# PIC32MM0064GPL036 register map
Vendor: Microchip
Registers are 32-bit, read-write, reset 0x0 unless marked. A register's access mark holds for its fields unless they carry their own. Addresses are absolute, and some are shared; only a register's first bit layout is shown; [hi:lo] are bit positions; {n}, {i} and the like mark numbered series.

## HLVD
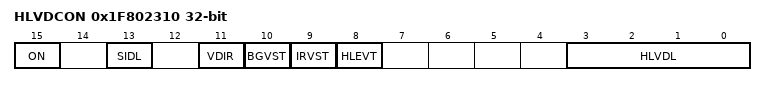
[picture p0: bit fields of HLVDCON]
0x1F802310 HLVDCON
  [15] ON, [13] SIDL, [11] VDIR, [10] BGVST, [9] IRVST, [8] HLEVT, [3:0] HLVDL

## NVM
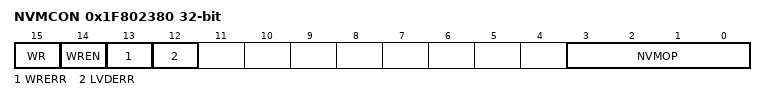
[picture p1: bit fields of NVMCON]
0x1F802380 NVMCON
  [15] WR, [14] WREN, [13] WRERR ro, [12] LVDERR, [3:0] NVMOP

## pfm_ctrl
0x1F802390 NVMKEY wo
0x1F8023A0 NVMADDR
0x1F8023B0 NVMDATA0
0x1F8023C0 NVMDATA1
0x1F8023D0 NVMSRCADDR
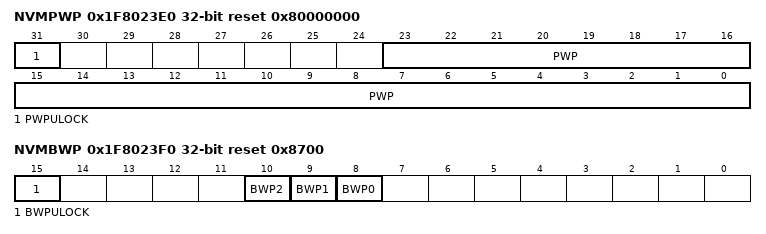
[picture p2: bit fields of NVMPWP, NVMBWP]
0x1F8023E0 NVMPWP reset 0x80000000
  [31] PWPULOCK — (can only be cleared)
  [23:0] PWP
0x1F8023F0 NVMBWP reset 0x8700
  [15] BWPULOCK — (can only be cleared)
  [10] BWP2
  [9] BWP1
  [8] BWP0

## INT
0x1F802480 RPCON
  [11] IOLOCK
0x1F8024A0 RPINR1
  [4:0] INT4R
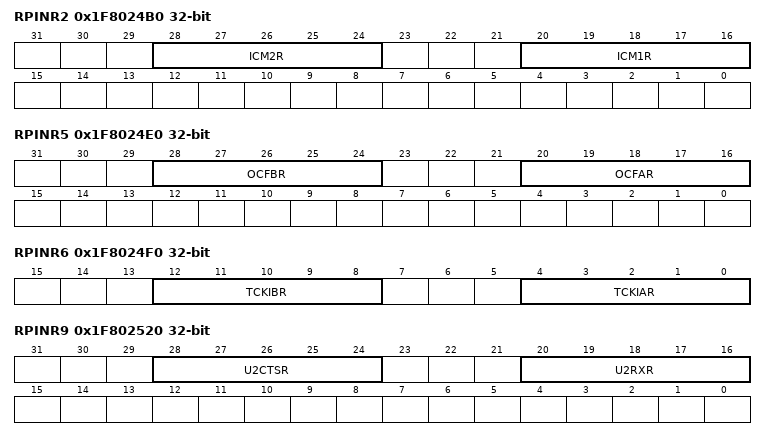
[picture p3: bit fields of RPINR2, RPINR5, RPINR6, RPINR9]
0x1F8024B0 RPINR2
  [28:24] ICM2R, [20:16] ICM1R
0x1F8024C0 RPINR3
  [4:0] ICM3R
0x1F8024E0 RPINR5
  [28:24] OCFBR, [20:16] OCFAR
0x1F8024F0 RPINR6
  [12:8] TCKIBR, [4:0] TCKIAR
0x1F802520 RPINR9
  [28:24] U2CTSR, [20:16] U2RXR
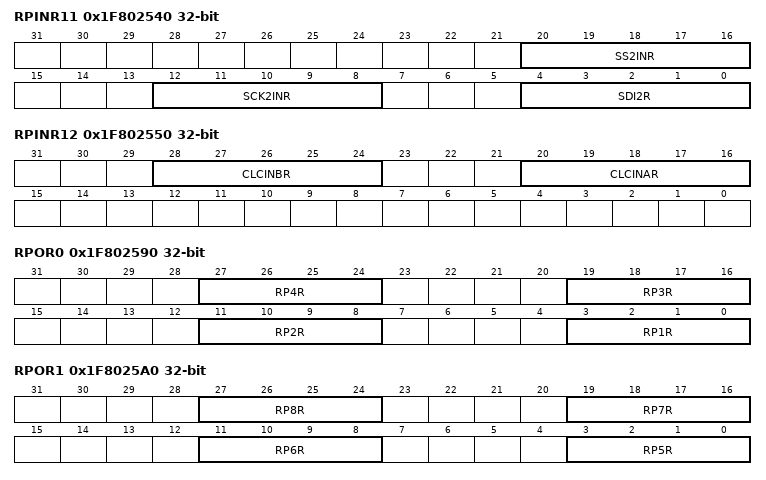
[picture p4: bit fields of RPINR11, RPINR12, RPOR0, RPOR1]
0x1F802540 RPINR11
  [20:16] SS2INR, [12:8] SCK2INR, [4:0] SDI2R
0x1F802550 RPINR12
  [28:24] CLCINBR, [20:16] CLCINAR
0x1F802590 RPOR0
  [8n-5:8n-8] RP{n}R (n=1..4)
0x1F8025A0 RPOR1
  [8n-37:8n-40] RP{n}R (n=5..8)
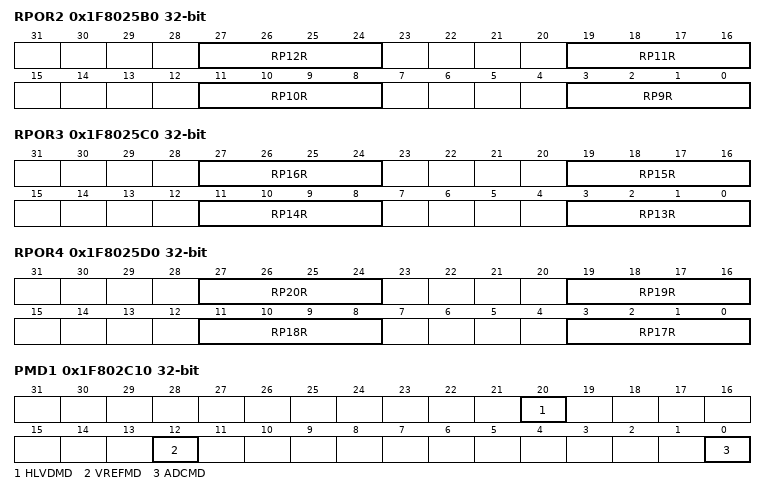
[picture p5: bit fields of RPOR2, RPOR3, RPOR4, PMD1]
0x1F8025B0 RPOR2
  [8n-69:8n-72] RP{n}R (n=9..12)
0x1F8025C0 RPOR3
  [8n-101:8n-104] RP{n}R (n=13..16)
0x1F8025D0 RPOR4
  [8n-133:8n-136] RP{n}R (n=17..20)
0x1F802C00 PMDCON
  [11] PMDLOCK
0x1F802C10 PMD1
  [20] HLVDMD, [12] VREFMD, [0] ADCMD
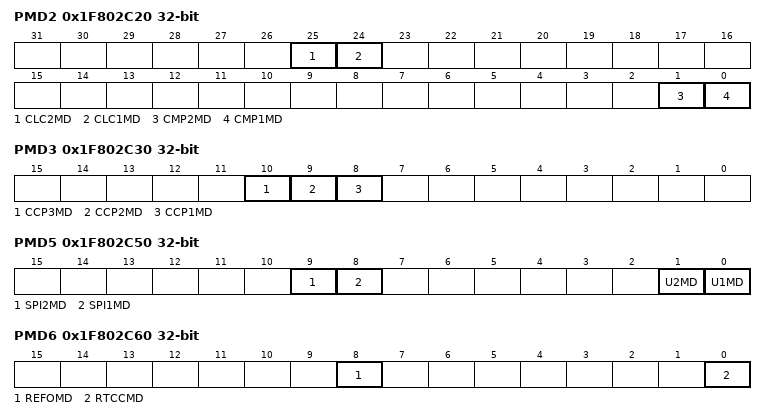
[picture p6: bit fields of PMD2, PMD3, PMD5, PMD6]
0x1F802C20 PMD2
  [25] CLC2MD, [24] CLC1MD, [1] CMP2MD, [0] CMP1MD
0x1F802C30 PMD3
  [10] CCP3MD, [9] CCP2MD, [8] CCP1MD
0x1F802C40 PMD4
  [0] T1MD
0x1F802C50 PMD5
  [9] SPI2MD, [8] SPI1MD, [1] U2MD, [0] U1MD
0x1F802C60 PMD6
  [8] REFOMD, [0] RTCCMD
0x1F802C70 PMD7
  [3] CRCMD
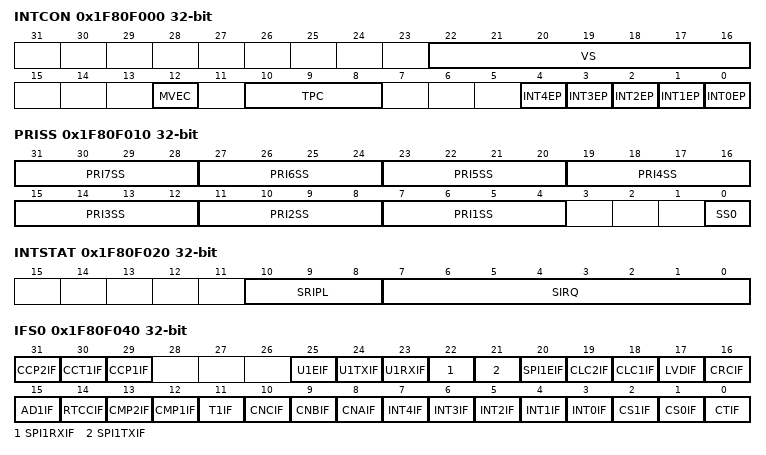
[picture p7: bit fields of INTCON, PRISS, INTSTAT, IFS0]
0x1F80F000 INTCON reset not defined — (power-on value ---------0000000-x-0-000---00000)
  [22:16] VS, [12] MVEC, [10:8] TPC, [n] INT{n}EP (n=0..4)
0x1F80F010 PRISS
  [4n+3:4n] PRI{n}SS (n=1..7), [0] SS0
0x1F80F020 INTSTAT ro
  [10:8] SRIPL, [7:0] SIRQ
0x1F80F030 IPTMR
0x1F80F040 IFS0
  [31] CCP2IF, [30] CCT1IF, [29] CCP1IF, [25] U1EIF, [24] U1TXIF, [23] U1RXIF, [22] SPI1RXIF, [21] SPI1TXIF, [20] SPI1EIF, [19] CLC2IF, [18] CLC1IF, [17] LVDIF, [16] CRCIF, [15] AD1IF, [14] RTCCIF, [13] CMP2IF, [12] CMP1IF, [11] T1IF, [10] CNCIF, [9] CNBIF, [8] CNAIF, [n+3] INT{n}IF (n=0..4), [2] CS1IF, [1] CS0IF, [0] CTIF
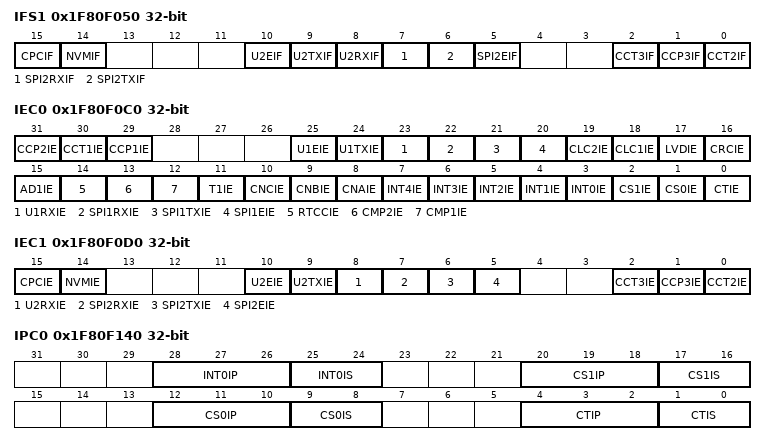
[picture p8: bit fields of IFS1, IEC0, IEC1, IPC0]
0x1F80F050 IFS1
  [15] CPCIF, [14] NVMIF, [10] U2EIF, [9] U2TXIF, [8] U2RXIF, [7] SPI2RXIF, [6] SPI2TXIF, [5] SPI2EIF, [2] CCT3IF, [1] CCP3IF, [0] CCT2IF
0x1F80F0C0 IEC0
  [31] CCP2IE, [30] CCT1IE, [29] CCP1IE, [25] U1EIE, [24] U1TXIE, [23] U1RXIE, [22] SPI1RXIE, [21] SPI1TXIE, [20] SPI1EIE, [19] CLC2IE, [18] CLC1IE, [17] LVDIE, [16] CRCIE, [15] AD1IE, [14] RTCCIE, [13] CMP2IE, [12] CMP1IE, [11] T1IE, [10] CNCIE, [9] CNBIE, [8] CNAIE, [n+3] INT{n}IE (n=0..4), [2] CS1IE, [1] CS0IE, [0] CTIE
0x1F80F0D0 IEC1
  [15] CPCIE, [14] NVMIE, [10] U2EIE, [9] U2TXIE, [8] U2RXIE, [7] SPI2RXIE, [6] SPI2TXIE, [5] SPI2EIE, [2] CCT3IE, [1] CCP3IE, [0] CCT2IE
0x1F80F140 IPC0
  [28:26] INT0IP, [25:24] INT0IS, [20:18] CS1IP, [17:16] CS1IS, [12:10] CS0IP, [9:8] CS0IS, [4:2] CTIP, [1:0] CTIS
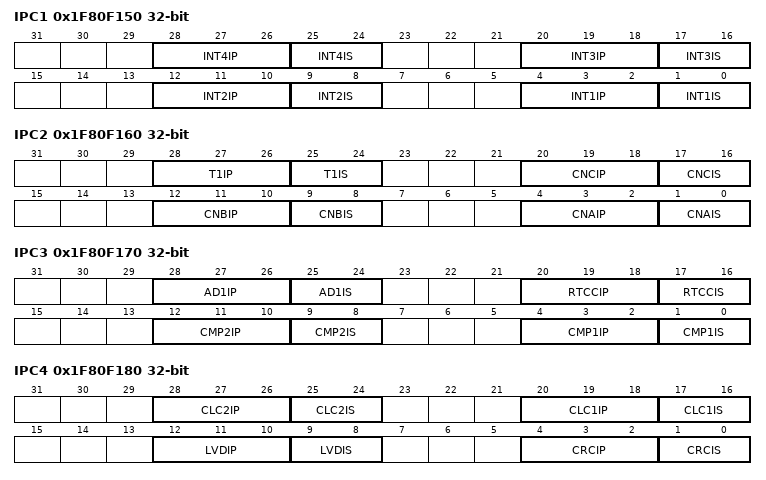
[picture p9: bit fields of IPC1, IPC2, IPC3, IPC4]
0x1F80F150 IPC1
  [8n-4:8n-6] INT{n}IP (n=1..4), [8n-7:8n-8] INT{n}IS (n=1..4)
0x1F80F160 IPC2
  [28:26] T1IP, [25:24] T1IS, [20:18] CNCIP, [17:16] CNCIS, [12:10] CNBIP, [9:8] CNBIS, [4:2] CNAIP, [1:0] CNAIS
0x1F80F170 IPC3
  [28:26] AD1IP, [25:24] AD1IS, [20:18] RTCCIP, [17:16] RTCCIS, [12:10] CMP2IP, [9:8] CMP2IS, [4:2] CMP1IP, [1:0] CMP1IS
0x1F80F180 IPC4
  [28:26] CLC2IP, [25:24] CLC2IS, [20:18] CLC1IP, [17:16] CLC1IS, [12:10] LVDIP, [9:8] LVDIS, [4:2] CRCIP, [1:0] CRCIS
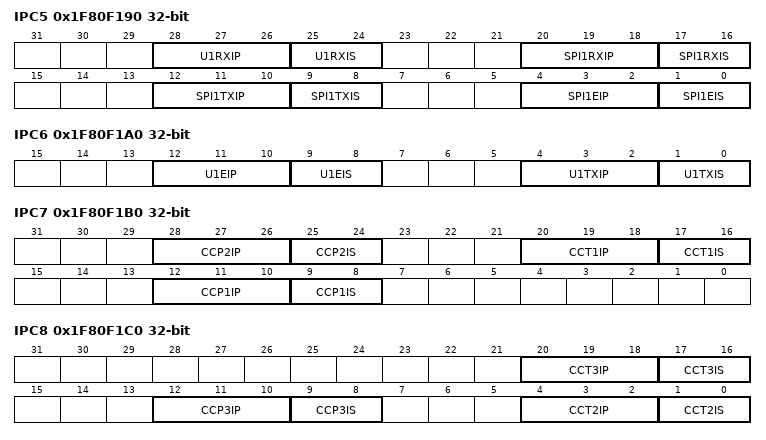
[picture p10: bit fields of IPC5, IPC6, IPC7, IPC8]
0x1F80F190 IPC5
  [28:26] U1RXIP, [25:24] U1RXIS, [20:18] SPI1RXIP, [17:16] SPI1RXIS, [12:10] SPI1TXIP, [9:8] SPI1TXIS, [4:2] SPI1EIP, [1:0] SPI1EIS
0x1F80F1A0 IPC6
  [12:10] U1EIP, [9:8] U1EIS, [4:2] U1TXIP, [1:0] U1TXIS
0x1F80F1B0 IPC7
  [28:26] CCP2IP, [25:24] CCP2IS, [20:18] CCT1IP, [17:16] CCT1IS, [12:10] CCP1IP, [9:8] CCP1IS
0x1F80F1C0 IPC8
  [20:18] CCT3IP, [17:16] CCT3IS, [12:10] CCP3IP, [9:8] CCP3IS, [4:2] CCT2IP, [1:0] CCT2IS
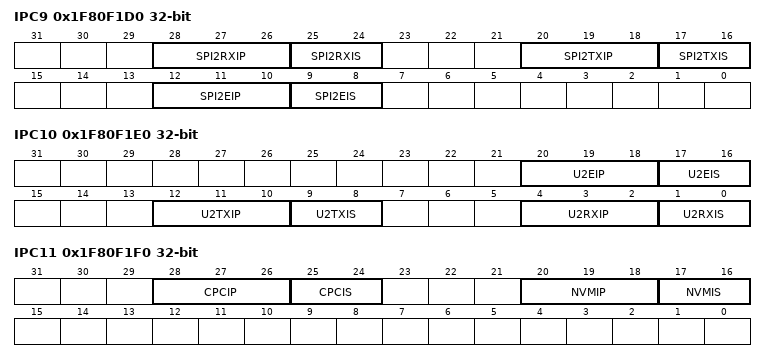
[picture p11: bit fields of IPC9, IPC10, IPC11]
0x1F80F1D0 IPC9
  [28:26] SPI2RXIP, [25:24] SPI2RXIS, [20:18] SPI2TXIP, [17:16] SPI2TXIS, [12:10] SPI2EIP, [9:8] SPI2EIS
0x1F80F1E0 IPC10
  [20:18] U2EIP, [17:16] U2EIS, [12:10] U2TXIP, [9:8] U2TXIS, [4:2] U2RXIP, [1:0] U2RXIS
0x1F80F1F0 IPC11
  [28:26] CPCIP, [25:24] CPCIS, [20:18] NVMIP, [17:16] NVMIS
